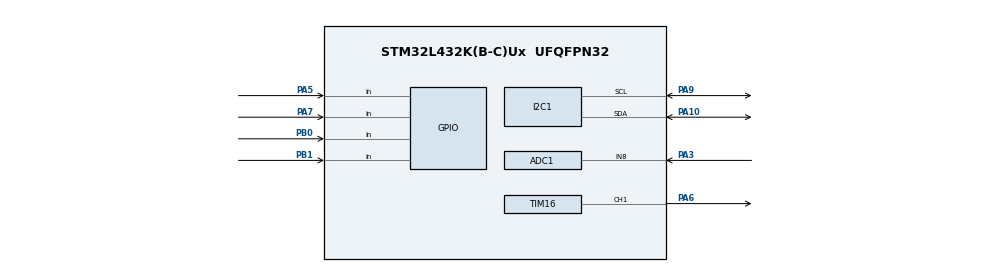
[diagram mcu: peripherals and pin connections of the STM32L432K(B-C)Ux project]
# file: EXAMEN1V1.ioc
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ADC1.Channel-0\#ChannelRegularConversion=ADC_CHANNEL_8
ADC1.NbrOfConversionFlag=1
ADC1.OffsetNumber-0\#ChannelRegularConversion=ADC_OFFSET_NONE
ADC1.Rank-0\#ChannelRegularConversion=1
ADC1.SamplingTime-0\#ChannelRegularConversion=ADC_SAMPLETIME_2CYCLES_5
ADC1.master=1
Dma.ADC1.0.Direction=DMA_PERIPH_TO_MEMORY
Dma.ADC1.0.Instance=DMA1_Channel1
Dma.ADC1.0.MemDataAlignment=DMA_MDATAALIGN_HALFWORD
Dma.ADC1.0.MemInc=DMA_MINC_ENABLE
Dma.ADC1.0.Mode=DMA_NORMAL
Dma.ADC1.0.PeriphDataAlignment=DMA_PDATAALIGN_HALFWORD
Dma.ADC1.0.PeriphInc=DMA_PINC_DISABLE
Dma.ADC1.0.Priority=DMA_PRIORITY_LOW
Dma.Request0=ADC1
Mcu.Family=STM32L4
Mcu.Name=STM32L432K(B-C)Ux
Mcu.Package=UFQFPN32
NVIC.DMA1_Channel1_IRQn=true\:0\:0\:false\:false\:true\:false\:true\:true
NVIC.PriorityGroup=NVIC_PRIORITYGROUP_4
PA10.Mode=I2C
PA10.Signal=I2C1_SDA
PA3.Signal=ADCx_IN8
PA5.GPIO_PuPd=GPIO_PULLUP
PA5.Signal=GPIO_Input
PA6.Signal=S_TIM16_CH1
PA7.GPIO_PuPd=GPIO_PULLUP
PA7.Signal=GPIO_Input
PA9.Mode=I2C
PA9.Signal=I2C1_SCL
PB0.GPIO_PuPd=GPIO_PULLUP
PB0.Signal=GPIO_Input
PB1.GPIO_PuPd=GPIO_PULLUP
PB1.Signal=GPIO_Input
ProjectManager.HeapSize=0x200
ProjectManager.StackSize=0x400
ProjectManager.TargetToolchain=STM32CubeIDE
RCC.HSE_VALUE=8000000
RCC.HSI48_VALUE=48000000
RCC.HSI_VALUE=16000000
RCC.LSE_VALUE=32768
RCC.MSI_VALUE=4000000
RCC.VCOOutputFreq_Value=32000000
SH.ADCx_IN8.0=ADC1_IN8,IN8-Single-Ended
SH.S_TIM16_CH1.0=TIM16_CH1,PWM Generation1 CH1
TIM16.Channel=TIM_CHANNEL_1
TIM16.Period=1000
TIM16.Prescaler=19
TIM16.Pulse=500
VP_TIM16_VS_ClockSourceINT.Mode=Enable_Timer
board=custom

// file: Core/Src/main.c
/* USER CODE BEGIN Header */
/**
  ******************************************************************************
  * @file           : main.c
  * @brief          : Main program body
  ******************************************************************************
  * @attention
  *
  * Copyright (c) 2022 STMicroelectronics.
  * All rights reserved.
  *
  * This software is licensed under terms that can be found in the LICENSE file
  * in the root directory of this software component.
  * If no LICENSE file comes with this software, it is provided AS-IS.
  *
  ******************************************************************************
  */
/* USER CODE END Header */
#include "main.h"
#include "liquidcrystal_i2c.h"
#include <string.h>
#include <stdio.h>

ADC_HandleTypeDef hadc1;
DMA_HandleTypeDef hdma_adc1;
unsigned readValue;

I2C_HandleTypeDef hi2c1;

TIM_HandleTypeDef htim16;

void SystemClock_Config(void);
static void MX_GPIO_Init(void);
static void MX_DMA_Init(void);
static void MX_I2C1_Init(void);
static void MX_TIM16_Init(void);
static void MX_ADC1_Init(void);

int main(void)
{

  /* MCU Configuration--------------------------------------------------------*/

  /* Reset of all peripherals, Initializes the Flash interface and the Systick. */
  HAL_Init();

  /* Configure the system clock */
  SystemClock_Config();

  /* Initialize all configured peripherals */
  MX_GPIO_Init();
  MX_DMA_Init();
  MX_I2C1_Init();
  MX_TIM16_Init();
  MX_ADC1_Init();

  /* USER CODE BEGIN 2 */
  HD44780_Init(2);

  /* USER CODE END 2 */

  /* Infinite loop */
  while (1)
  {
	  HD44780_Clear();
	   HD44780_SetCursor(0,0);
	   HD44780_PrintStr("INICIANDO...");
	   HAL_Delay(5000);
	   HD44780_SetCursor(0,1);
	   HD44780_PrintStr("MAQUINA DISPENSADORA");
	   HAL_Delay(2000);
	   HAL_TIM_PWM_Start(&htim16, TIM_CHANNEL_1);

	   HD44780_Clear();
	   HD44780_SetCursor(0,0);
	   HD44780_PrintStr("Ingrese monedas: ");
	   HAL_Delay(1000);
	   int aux=0;
	   float monedasT=0;
	   while(aux==0){
		   if(!(HAL_GPIO_ReadPin (GPIOA, GPIO_PIN_6))){
		   	 		  HD44780_SetCursor(12,1);
		   	 		  HD44780_PrintStr("0.10Bs");
		   	 		  monedasT=monedasT+1;
		   	 		  HAL_Delay(500);
		   	 	  }
		   if(!(HAL_GPIO_ReadPin (GPIOA, GPIO_PIN_2))){
		   	 		  HD44780_SetCursor(12,1);
		   	 		  HD44780_PrintStr("0.20Bs");
		   	 		  monedasT=monedasT+1;
		   	 		  HAL_Delay(500);
		   	 	  }
		   if(!(HAL_GPIO_ReadPin (GPIOA, GPIO_PIN_5))){
		   	 		  HD44780_SetCursor(12,1);
		   	 		  HD44780_PrintStr("0.5Bs");
		   	 		  monedasT=monedasT+1;
		   	 		  HAL_Delay(500);
		   	 	  }
	 	  if(!(HAL_GPIO_ReadPin (GPIOA, GPIO_PIN_8))){
	 		  HD44780_SetCursor(12,1);
	 		  HD44780_PrintStr("1Bs");
	 		  monedasT=monedasT+1;
	 		  HAL_Delay(500);
	 	  }
	 	  if(!(HAL_GPIO_ReadPin (GPIOA, GPIO_PIN_7))){
	 		  HD44780_SetCursor(12,1);
	 		  HD44780_PrintStr("2Bs");
	 		  monedasT=monedasT+2;
	 		  HAL_Delay(500);
	 	  }
	 	  if(!(HAL_GPIO_ReadPin (GPIOB, GPIO_PIN_0))){
	 		  HD44780_SetCursor(12,1);
	 		  HD44780_PrintStr("5Bs");
	 		  monedasT=monedasT+5;
	 		  HAL_Delay(500);
	 	  }
	 	 HD44780_SetCursor(0,1);
	 	 HD44780_PrintStr("TOTAL:");
	 	HD44780_SetCursor(6,1);
	 	char buf[100];
	 	 gcvt(monedasT, 6, buf);
	 	HD44780_PrintStr(buf);
	 		 		  HD44780_SetCursor(9,1);
	 		 		  HD44780_PrintStr("Bs");
	 	  if(!(HAL_GPIO_ReadPin (GPIOB, GPIO_PIN_1))){
	 		  HD44780_Clear();
	 		  HD44780_SetCursor(0,0);
	 		  HD44780_PrintStr("SALDO:");
	 		  HD44780_SetCursor(7,0);
	 		  char buf[100];
	 		  gcvt(monedasT, 6, buf);
	 		  HD44780_PrintStr(buf);
	 		  HD44780_SetCursor(9,0);
	 		  HD44780_PrintStr("Bs.");
	 		  HAL_Delay(3000);

	 		  HD44780_Clear();
	 		  HD44780_SetCursor(0,0);
	 		  HD44780_PrintStr("seleccione producto");
	 		  HAL_Delay(2000);
	 		  aux=1;
	 	  }
	   }
	   int aux2=0;
	   HD44780_Clear();
		  HD44780_SetCursor(0,0);
		  HD44780_PrintStr("MOVER PERILLA");
		  HAL_Delay(2000);
	   while(aux2==0){
	 	  HAL_ADC_Start(&hadc1);
	 	  readValue=HAL_ADC_GetValue(&hadc1);

	 	  if(HAL_ADC_GetValue(&hadc1)>0 && HAL_ADC_GetValue(&hadc1)<500){
	 	  		  HD44780_SetCursor(0,0);
	 	  		HD44780_Clear();
	 	  		  HD44780_PrintStr("Producto 1: 1Bs");

	 	  		if((monedasT-1)>=0){
	 	  			HD44780_SetCursor(0,1);
	 	  			  	 HD44780_PrintStr("vuelto ");
	 	  			  	HD44780_SetCursor(7,1);
	 	  			  char buf[100];
	 	  			  		  gcvt(monedasT-1, 6, buf);
	 	  			  		  			  	 HD44780_PrintStr(buf);
	 	  			  		  			HD44780_SetCursor(11,1);
	 	  			  		  			  	 HD44780_PrintStr("Bs");
	 	  		}
	 	  		else if((monedasT-1)<0){
	 	  			HD44780_SetCursor(0,1);
	  			  	 HD44780_PrintStr("saldo insuficiente");

	  		}
	 	  		  HAL_Delay(300);
	 	  }
	 	  if(HAL_ADC_GetValue(&hadc1)>500 && HAL_ADC_GetValue(&hadc1)<1000){
	 	  		  HD44780_SetCursor(0,0);
	 	  		HD44780_Clear();
	 	  		  HD44780_PrintStr("Producto 2: 4Bs");
	 	  		if((monedasT-4)>=0){
	 	  			  			HD44780_SetCursor(0,1);
	 	  			  			  	 HD44780_PrintStr("vuelto ");
	 	  			  			  	HD44780_SetCursor(7,1);
	 	  			  			  char buf[100];
	 	  			  			  		  gcvt(monedasT-4, 6, buf);
	 	  			  			  		  			  	 HD44780_PrintStr(buf);
	 	  			  			  		  		HD44780_SetCursor(11,1);
	 	  			  			  	HD44780_PrintStr("Bs");
	 	  			  		}
	 	  			  		else if((monedasT-4)<0){
	 	  			  			HD44780_SetCursor(0,1);
	 	  		 			  	 HD44780_PrintStr("saldo insuficiente");

	 	  		 		}
	 	  		  HAL_Delay(300);
	 	  }
	 	  if(HAL_ADC_GetValue(&hadc1)>1000 && HAL_ADC_GetValue(&hadc1)<1500){
	 		  	  HD44780_SetCursor(0,0);
	 		  	HD44780_Clear();
	 		  	  HD44780_PrintStr("Producto 3: 6Bs");
	 		  	if((monedasT-6)>=0){
	 		  		  			  			HD44780_SetCursor(0,1);
	 		  		  			  			  	 HD44780_PrintStr("vuelto ");
	 		  		  			  			  	HD44780_SetCursor(7,1);
	 		  		  			  			  char buf[100];
	 		  		  			  			  		  gcvt(monedasT-6, 6, buf);
	 		  		  			  			  		  			  	 HD44780_PrintStr(buf);
	 		  		  			  			  		  		HD44780_SetCursor(11,1);
	 		  		  			  	HD44780_PrintStr("Bs");
	 		  		  			  		}
	 		  		  			  		else if((monedasT-6)<0){
	 		  		  			  			HD44780_SetCursor(0,1);
	 		  		  		 			  	 HD44780_PrintStr("saldo insuficiente");

	 		  		  		 		}
	 		  	  HAL_Delay(300);
	 	  }
	 	  if(HAL_ADC_GetValue(&hadc1)>1500 && HAL_ADC_GetValue(&hadc1)<2000){
	 	  	  	  HD44780_SetCursor(0,0);
	 	  	  	HD44780_Clear();
	 	  	  	  HD44780_PrintStr("Producto 4: 2Bs");
	 	  	  	if((monedasT-2)>=0){
	 	  	  		  			  			HD44780_SetCursor(0,1);
	 	  	  		  			  			  	 HD44780_PrintStr("vuelto ");
	 	  	  		  			  			  	HD44780_SetCursor(7,1);
	 	  	  		  			  			  char buf[100];
	 	  	  		  			  			  		  gcvt(monedasT-2, 6, buf);
	 	  	  		  			  			  		  			  	 HD44780_PrintStr(buf);
	 	  	  		  			  			  		  	HD44780_SetCursor(11,1);
	 	  	  		  			  			  		  	HD44780_PrintStr("Bs");
	 	  	  		  			  		}
	 	  	  		  			  		else if((monedasT-2)<0){
	 	  	  		  			  			HD44780_SetCursor(0,1);
	 	  	  		  		 			  	 HD44780_PrintStr("saldo insuficiente");

	 	  	  		  		 		}
	 	  	  	  HAL_Delay(300);
	 	  }
	 	  if(HAL_ADC_GetValue(&hadc1)>2000 && HAL_ADC_GetValue(&hadc1)<2500){
	 		  	  HD44780_SetCursor(0,0);
	 		  	HD44780_Clear();
	 		  	  HD44780_PrintStr("Producto 5: 5Bs");
	 	  		if((monedasT-5)>=0){
	 	  			  			  			HD44780_SetCursor(0,1);
	 	  			  			  			  	 HD44780_PrintStr("vuelto ");
	 	  			  			  			  	HD44780_SetCursor(7,1);
	 	  			  			  			  char buf[100];
	 	  			  			  			  		  gcvt(monedasT-5, 6, buf);
	 	  			  			  			  		  			  	 HD44780_PrintStr(buf);
	 	  			  			  			  		  		HD44780_SetCursor(11,1);
	 	  			  			  			  		  	 HD44780_PrintStr("Bs");
	 	  			  			  		}
	 	  			  			  		else if((monedasT-5)<0){
	 	  			  			  			HD44780_SetCursor(0,1);
	 	  			  		 			  	 HD44780_PrintStr("saldo insuficiente");

	 	  			  		 		}
	 	  		  HAL_Delay(300);
	 	  }
	 	  if(HAL_ADC_GetValue(&hadc1)>2500 && HAL_ADC_GetValue(&hadc1)<3000){
	 	  		  HD44780_SetCursor(0,0);
	 	  		HD44780_Clear();
	 	  		  HD44780_PrintStr("Producto 6: 10Bs");
	 	  		if((monedasT-10)>=0){
	 	  			  			  			HD44780_SetCursor(0,1);
	 	  			  			  			  	 HD44780_PrintStr("vuelto ");
	 	  			  			  			  	HD44780_SetCursor(7,1);
	 	  			  			  			  char buf[100];
	 	  			  			  			  		  gcvt(monedasT-10, 6, buf);
	 	  			  			  			  		  			  	 HD44780_PrintStr(buf);
	 	  			  			  			  		  		HD44780_SetCursor(11,1);
	 	  			  			  			  		  		HD44780_PrintStr("Bs");
	 	  			  			  		}
	 	  			  			  		else if((monedasT-10)<0){
	 	  			  			  			HD44780_SetCursor(0,1);
	 	  			  		 			  	 HD44780_PrintStr("saldo insuficiente");

	 	  			  		 		}
	 	  		  HAL_Delay(300);
	 	  }
	 	  if(!(HAL_GPIO_ReadPin (GPIOB, GPIO_PIN_1))){
	 		  	  HD44780_Clear();
	 		  	  HD44780_SetCursor(0,0);
	 		  	  HD44780_PrintStr("dropeando el producto....");
	 		  	  HAL_Delay(500);
	 		  	  aux2=1;
	 	  }
	   }
	   int x;
	   for(x=50;x<600;x++){
	   		  __HAL_TIM_SET_COMPARE(&htim16,TIM_CHANNEL_1,x);
	   		  HAL_Delay(3);
	   }
	   HD44780_Clear();
	   HD44780_SetCursor(0,0);
	   HD44780_PrintStr("RECOJER PRODUCTO");
	   HAL_Delay(3000);
  }
}

void SystemClock_Config(void)
{
  RCC_OscInitTypeDef RCC_OscInitStruct = {0};
  RCC_ClkInitTypeDef RCC_ClkInitStruct = {0};

  /** Configure the main internal regulator output voltage
  */
  if (HAL_PWREx_ControlVoltageScaling(PWR_REGULATOR_VOLTAGE_SCALE1) != HAL_OK)
  {
    Error_Handler();
  }

  /** Initializes the RCC Oscillators according to the specified parameters
  * in the RCC_OscInitTypeDef structure.
  */
  RCC_OscInitStruct.OscillatorType = RCC_OSCILLATORTYPE_MSI;
  RCC_OscInitStruct.MSIState = RCC_MSI_ON;
  RCC_OscInitStruct.MSICalibrationValue = 0;
  RCC_OscInitStruct.MSIClockRange = RCC_MSIRANGE_6;
  RCC_OscInitStruct.PLL.PLLState = RCC_PLL_NONE;
  if (HAL_RCC_OscConfig(&RCC_OscInitStruct) != HAL_OK)
  {
    Error_Handler();
  }

  /** Initializes the CPU, AHB and APB buses clocks
  */
  RCC_ClkInitStruct.ClockType = RCC_CLOCKTYPE_HCLK|RCC_CLOCKTYPE_SYSCLK
                              |RCC_CLOCKTYPE_PCLK1|RCC_CLOCKTYPE_PCLK2;
  RCC_ClkInitStruct.SYSCLKSource = RCC_SYSCLKSOURCE_MSI;
  RCC_ClkInitStruct.AHBCLKDivider = RCC_SYSCLK_DIV1;
  RCC_ClkInitStruct.APB1CLKDivider = RCC_HCLK_DIV1;
  RCC_ClkInitStruct.APB2CLKDivider = RCC_HCLK_DIV1;

  if (HAL_RCC_ClockConfig(&RCC_ClkInitStruct, FLASH_LATENCY_0) != HAL_OK)
  {
    Error_Handler();
  }
}

static void MX_ADC1_Init(void)
{

  ADC_ChannelConfTypeDef sConfig = {0};

  /** Common config
  */
  hadc1.Instance = ADC1;
  hadc1.Init.ClockPrescaler = ADC_CLOCK_ASYNC_DIV1;
  hadc1.Init.Resolution = ADC_RESOLUTION_12B;
  hadc1.Init.DataAlign = ADC_DATAALIGN_RIGHT;
  hadc1.Init.ScanConvMode = ADC_SCAN_DISABLE;
  hadc1.Init.EOCSelection = ADC_EOC_SINGLE_CONV;
  hadc1.Init.LowPowerAutoWait = DISABLE;
  hadc1.Init.ContinuousConvMode = DISABLE;
  hadc1.Init.NbrOfConversion = 1;
  hadc1.Init.DiscontinuousConvMode = DISABLE;
  hadc1.Init.ExternalTrigConv = ADC_SOFTWARE_START;
  hadc1.Init.ExternalTrigConvEdge = ADC_EXTERNALTRIGCONVEDGE_NONE;
  hadc1.Init.DMAContinuousRequests = DISABLE;
  hadc1.Init.Overrun = ADC_OVR_DATA_PRESERVED;
  hadc1.Init.OversamplingMode = DISABLE;
  if (HAL_ADC_Init(&hadc1) != HAL_OK)
  {
    Error_Handler();
  }

  /** Configure Regular Channel
  */
  sConfig.Channel = ADC_CHANNEL_8;
  sConfig.Rank = ADC_REGULAR_RANK_1;
  sConfig.SamplingTime = ADC_SAMPLETIME_2CYCLES_5;
  sConfig.SingleDiff = ADC_SINGLE_ENDED;
  sConfig.OffsetNumber = ADC_OFFSET_NONE;
  sConfig.Offset = 0;
  if (HAL_ADC_ConfigChannel(&hadc1, &sConfig) != HAL_OK)
  {
    Error_Handler();
  }

}

static void MX_I2C1_Init(void)
{

  hi2c1.Instance = I2C1;
  hi2c1.Init.Timing = 0x00000E14;
  hi2c1.Init.OwnAddress1 = 0;
  hi2c1.Init.AddressingMode = I2C_ADDRESSINGMODE_7BIT;
  hi2c1.Init.DualAddressMode = I2C_DUALADDRESS_DISABLE;
  hi2c1.Init.OwnAddress2 = 0;
  hi2c1.Init.OwnAddress2Masks = I2C_OA2_NOMASK;
  hi2c1.Init.GeneralCallMode = I2C_GENERALCALL_DISABLE;
  hi2c1.Init.NoStretchMode = I2C_NOSTRETCH_DISABLE;
  if (HAL_I2C_Init(&hi2c1) != HAL_OK)
  {
    Error_Handler();
  }

  /** Configure Analogue filter
  */
  if (HAL_I2CEx_ConfigAnalogFilter(&hi2c1, I2C_ANALOGFILTER_ENABLE) != HAL_OK)
  {
    Error_Handler();
  }

  /** Configure Digital filter
  */
  if (HAL_I2CEx_ConfigDigitalFilter(&hi2c1, 0) != HAL_OK)
  {
    Error_Handler();
  }

}

static void MX_TIM16_Init(void)
{

  TIM_OC_InitTypeDef sConfigOC = {0};
  TIM_BreakDeadTimeConfigTypeDef sBreakDeadTimeConfig = {0};

  htim16.Instance = TIM16;
  htim16.Init.Prescaler = 19;
  htim16.Init.CounterMode = TIM_COUNTERMODE_UP;
  htim16.Init.Period = 1000;
  htim16.Init.ClockDivision = TIM_CLOCKDIVISION_DIV1;
  htim16.Init.RepetitionCounter = 0;
  htim16.Init.AutoReloadPreload = TIM_AUTORELOAD_PRELOAD_DISABLE;
  if (HAL_TIM_Base_Init(&htim16) != HAL_OK)
  {
    Error_Handler();
  }
  if (HAL_TIM_PWM_Init(&htim16) != HAL_OK)
  {
    Error_Handler();
  }
  sConfigOC.OCMode = TIM_OCMODE_PWM1;
  sConfigOC.Pulse = 500;
  sConfigOC.OCPolarity = TIM_OCPOLARITY_HIGH;
  sConfigOC.OCNPolarity = TIM_OCNPOLARITY_HIGH;
  sConfigOC.OCFastMode = TIM_OCFAST_DISABLE;
  sConfigOC.OCIdleState = TIM_OCIDLESTATE_RESET;
  sConfigOC.OCNIdleState = TIM_OCNIDLESTATE_RESET;
  if (HAL_TIM_PWM_ConfigChannel(&htim16, &sConfigOC, TIM_CHANNEL_1) != HAL_OK)
  {
    Error_Handler();
  }
  sBreakDeadTimeConfig.OffStateRunMode = TIM_OSSR_DISABLE;
  sBreakDeadTimeConfig.OffStateIDLEMode = TIM_OSSI_DISABLE;
  sBreakDeadTimeConfig.LockLevel = TIM_LOCKLEVEL_OFF;
  sBreakDeadTimeConfig.DeadTime = 0;
  sBreakDeadTimeConfig.BreakState = TIM_BREAK_DISABLE;
  sBreakDeadTimeConfig.BreakPolarity = TIM_BREAKPOLARITY_HIGH;
  sBreakDeadTimeConfig.AutomaticOutput = TIM_AUTOMATICOUTPUT_DISABLE;
  if (HAL_TIMEx_ConfigBreakDeadTime(&htim16, &sBreakDeadTimeConfig) != HAL_OK)
  {
    Error_Handler();
  }
  HAL_TIM_MspPostInit(&htim16);

}

static void MX_DMA_Init(void)
{

  /* DMA controller clock enable */
  __HAL_RCC_DMA1_CLK_ENABLE();

  /* DMA interrupt init */
  /* DMA1_Channel1_IRQn interrupt configuration */
  HAL_NVIC_SetPriority(DMA1_Channel1_IRQn, 0, 0);
  HAL_NVIC_EnableIRQ(DMA1_Channel1_IRQn);

}

static void MX_GPIO_Init(void)
{
  GPIO_InitTypeDef GPIO_InitStruct = {0};

  /* GPIO Ports Clock Enable */
  __HAL_RCC_GPIOA_CLK_ENABLE();
  __HAL_RCC_GPIOB_CLK_ENABLE();

  /*Configure GPIO pins : PA5 PA7 */
  GPIO_InitStruct.Pin = GPIO_PIN_5|GPIO_PIN_7;
  GPIO_InitStruct.Mode = GPIO_MODE_INPUT;
  GPIO_InitStruct.Pull = GPIO_PULLUP;
  HAL_GPIO_Init(GPIOA, &GPIO_InitStruct);

  /*Configure GPIO pins : PB0 PB1 */
  GPIO_InitStruct.Pin = GPIO_PIN_0|GPIO_PIN_1;
  GPIO_InitStruct.Mode = GPIO_MODE_INPUT;
  GPIO_InitStruct.Pull = GPIO_PULLUP;
  HAL_GPIO_Init(GPIOB, &GPIO_InitStruct);

}

/* USER CODE BEGIN 4 */

	char enteroACaracter(int numero){
	    return numero + '0';
	}

/* USER CODE END 4 */

void Error_Handler(void)
{
  __disable_irq();
  while (1)
  {
  }
}
